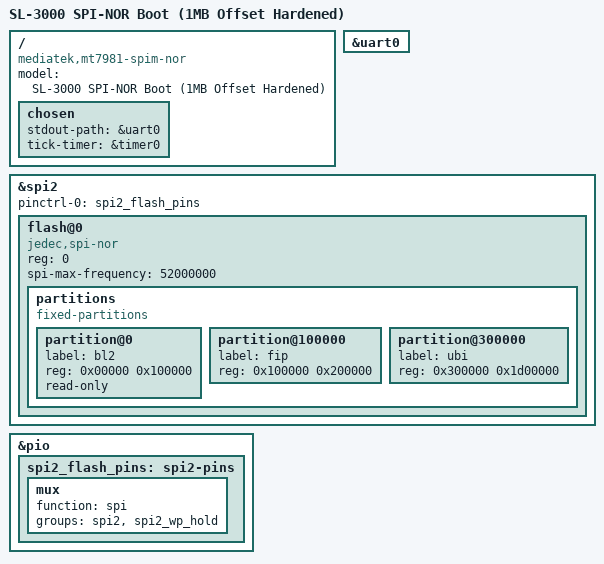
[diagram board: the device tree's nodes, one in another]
/dts-v1/;
#include "mt7981.dtsi"

/ {
	model = "SL-3000 SPI-NOR Boot (1MB Offset Hardened)";
	compatible = "mediatek,mt7981-spim-nor", "mediatek,mt7981";

	chosen {
		/* 物理串口锁定：确保 BL2 日志从 UART0 输出 */
		stdout-path = &uart0;
		tick-timer = &timer0;
	};
};

&uart0 {
	status = "okay";
};

/* * 物理链路修复：锁定 SPI2 控制器。
 * 注意：SL-3000 硬件引脚必须物理连接到 SPIM2 组（GPIO 23-28）。
 */
&spi2 {
	pinctrl-names = "default";
	pinctrl-0 = <&spi2_flash_pins>;
	status = "okay";

	flash@0 {
		compatible = "jedec,spi-nor";
		reg = <0>;
		/* 物理时钟锁定：52MHz 为兼容性最强的安全频率 */
		spi-max-frequency = <52000000>;
		#address-cells = <1>;
		#size-cells = <1>;

		/* --- 物理加固：分区表定义 --- */
		partitions {
			compatible = "fixed-partitions";
			#address-cells = <1>;
			#size-cells = <1>;

			/* * 物理区间 [0 - 1MB] 
			 * 预留给 BL2 主程序及备份空间 
			 */
			partition@0 {
				label = "bl2";
				reg = <0x00000 0x100000>;
				read-only;
			};

			/* * 物理区间 [1MB - 3MB]
			 * 物理命门：FIP (U-Boot/BL31) 必须从此地址 (0x100000) 开始 
			 */
			partition@100000 {
				label = "fip";
				reg = <0x100000 0x200000>;
			};

			/* * 物理区间 [3MB - 结束]
			 * 剩下的空间分配给 UBI 分区或存储
			 */
			partition@300000 {
				label = "ubi";
				reg = <0x300000 0x1d00000>; /* 假设为 32MB Flash */
			};
		};
	};
};

&pio {
	/* 物理引脚锁定：SPIM2 模式与引脚组 */
	spi2_flash_pins: spi2-pins {
		mux {
			function = "spi";
			groups = "spi2", "spi2_wp_hold";
		};
	};
};
